VERSION "HIPBYYYYYYYYYYYYYYYYYYYYYYYYYYYYNNNNNNNNNN/4/%%%/4/'%**4NNN///"

NS_ :

BS_:

BU_: THMM_00000 CSM_GmbH

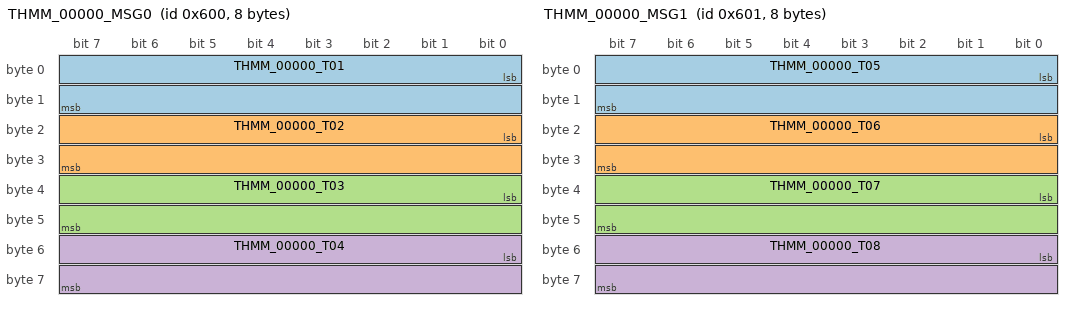
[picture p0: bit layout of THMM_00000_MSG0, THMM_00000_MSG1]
BO_ 1536 THMM_00000_MSG0: 8 THMM_00000
 SG_ THMM_00000_T01 : 0|16@1- (0.1,0) [-100|1372] "°C" CSM_GmbH
 SG_ THMM_00000_T02 : 16|16@1- (0.1,0) [-100|1372] "°C" CSM_GmbH
 SG_ THMM_00000_T03 : 32|16@1- (0.1,0) [-100|1372] "°C" CSM_GmbH
 SG_ THMM_00000_T04 : 48|16@1- (0.1,0) [-100|1372] "°C" CSM_GmbH

BO_ 1537 THMM_00000_MSG1: 8 THMM_00000
 SG_ THMM_00000_T05 : 0|16@1- (0.1,0) [-100|1372] "°C" CSM_GmbH
 SG_ THMM_00000_T06 : 16|16@1- (0.1,0) [-100|1372] "°C" CSM_GmbH
 SG_ THMM_00000_T07 : 32|16@1- (0.1,0) [-100|1372] "°C" CSM_GmbH
 SG_ THMM_00000_T08 : 48|16@1- (0.1,0) [-100|1372] "°C" CSM_GmbH

BA_DEF_  "BusType" STRING ;
BA_DEF_  "CSMconfigVersion" STRING ;
BA_DEF_  "CSMformatVersion" INT 0 255 ;
BA_DEF_ BO_ "GenMsgCycleTime" INT 0 0 ;
BA_DEF_ BO_ "GenMsgSendType" ENUM "Cyclic","not_used","not_used","not_used","not_used","Cyclic","not_used","IfActive","NoMsgSendType";
BA_DEF_ BO_ "CSMcycleTime" INT 0 0 ;
BA_DEF_ BU_ "CSMdeviceType" INT -1 3016 ;
BA_DEF_ BU_ "CSMdeviceDeviceType" INT -1 3016 ;
BA_DEF_ BU_ "CSMdeviceSerialNo" HEX 0 4294967295 ;
BA_DEF_ BU_ "CSMdeviceHash" HEX 0 0 ;
BA_DEF_ BU_ "CSMdeviceChannels" INT 0 16 ;
BA_DEF_  "CSMdata0000" STRING ;
BA_DEF_  "CSMdata0001" STRING ;
BA_DEF_  "CSMdata0002" STRING ;
BA_DEF_  "CSMdata0003" STRING ;
BA_DEF_  "CSMdata0004" STRING ;
BA_DEF_  "CSMdata0005" STRING ;
BA_DEF_  "CSMdata0006" STRING ;
BA_DEF_  "CSMdata0007" STRING ;

BA_DEF_DEF_ "BusType" "";
BA_DEF_DEF_ "CSMconfigVersion" "";
BA_DEF_DEF_ "CSMformatVersion" 0 ;
BA_DEF_DEF_ "GenMsgCycleTime" 0 ;
BA_DEF_DEF_ "GenMsgSendType" "NoMsgSendType";
BA_DEF_DEF_ "CSMcycleTime" 0 ;
BA_DEF_DEF_ "CSMdeviceType" -1 ;
BA_DEF_DEF_ "CSMdeviceDeviceType" -1 ;
BA_DEF_DEF_ "CSMdeviceSerialNo" 0 ;
BA_DEF_DEF_ "CSMdeviceHash" 0 ;
BA_DEF_DEF_ "CSMdeviceChannels" 0 ;
BA_DEF_DEF_ "CSMdata0000" "";
BA_DEF_DEF_ "CSMdata0001" "";
BA_DEF_DEF_ "CSMdata0002" "";
BA_DEF_DEF_ "CSMdata0003" "";
BA_DEF_DEF_ "CSMdata0004" "";
BA_DEF_DEF_ "CSMdata0005" "";
BA_DEF_DEF_ "CSMdata0006" "";
BA_DEF_DEF_ "CSMdata0007" "";

BA_ "GenMsgCycleTime" BO_ 1536 100 ;
BA_ "GenMsgSendType" BO_ 1536 0;
BA_ "CSMcycleTime" BO_ 1536 100000 ;
BA_ "GenMsgCycleTime" BO_ 1537 100 ;
BA_ "GenMsgSendType" BO_ 1537 0;
BA_ "CSMcycleTime" BO_ 1537 100000 ;
BA_ "BusType"  "CAN";
BA_ "CSMconfigVersion"  "9.3.0.13055";
BA_ "CSMformatVersion"  2 ;
BA_ "CSMdeviceType" BU_ THMM_00000 3 ;
BA_ "CSMdeviceDeviceType" BU_ THMM_00000 10 ;
BA_ "CSMdeviceHash" BU_ THMM_00000 719172312 ;
BA_ "CSMdeviceChannels" BU_ THMM_00000 8 ;
BA_ "CSMdata0000"  "C20200007F0B000084EC340B78DAE5564D6F1A3110EDB952FFC3D4A7560DFBC186102220AAA8A21E420E0555BD45667796B5B46B6F6D03E15FF537F497756C932549A51E72ABD8CBCECED8CFEFBD1981C7D70F4D0D5BD4462839616994B0EBE9BBB7E3D9";
BA_ "CSMdata0001"  "629E2B598A358457B76214655112A55932183028956EB8ED6A7D068426CDD58311135659DB5EC5F16EB78B7659A4F43AEE27491AFF98DF2EF20A1BDE13D2582E73A45D465C199FBC5539B71EECC9F6DC345181F1915317450FA660D3F1FB5E0F1682A08E";
BA_ "CSMdata0002"  "155821B143F87E198DA204722EA5B2507159D408C401246FD0B43C477306D0EB05105B090385CA370D4A0B14E71AB9C50276C2566A63811FF781693117A50884A30EE34669D8F25A149497EB33686BE406811705C1237956D76A4715D058A246C7DA2A5F";
BA_ "CSMdata0003"  "D28A28628DEEF0231E0453FFE908EB562FAB202F780CA520B91F9EF9F5D1E9AA9DCFA44B487FB26F455D7B2550088DB9557A0FAA7C62B53F62F6F96EB531202C3665CDD7C42A63B0125613DA840D12F7D05C6832C9EE5B4AA52903C31B32A15542DA09BB";
BA_ "CSMdata0004"  "B860200A6A16794465060D3716B52826EC7C3818F5FBE7594A2DFD825B41BD790C5E9C58E036C08778CBB5E00E3CA5C30D6AA9262CF19543142454DC5413364C47E9B09FA534AD2DEA9C4642621D16B8B5D3F11D919F2EBFCEE7F75ECE38F60927DDA075";
BA_ "CSMdata0005"  "3D35AF51BCA221A0E220F35F24B9F5CC9E5A114FC74BCDA5698485009F3AECD5DEA2D205EAB04196AA319E2A9027ED21A6BDDFD0A87AE35BA8BBF0509B0599A68B5E189A5707F27FEBBF5F2669E7816ADC704EC771172D729A75B9BE1512B98692BBC999";
BA_ "CSMdata0006"  "B04FF41B913C7FC816559664A1AB32D84841D1EF5F33EA93306DCDF78D20B63D2FF931C31F68719A0DFB4EC38DA86950DC48D32BD075CEFBCF52E3CF83D4F8A0F07552FBA723353B1DA9E7A72375703A522F4E47EAF074A45EFE9F52E3E35F6C1CEE2C5D";
BA_ "CSMdata0007"  "E052E1E2E482C70B155DB3DFFC0111EBA9A5";
